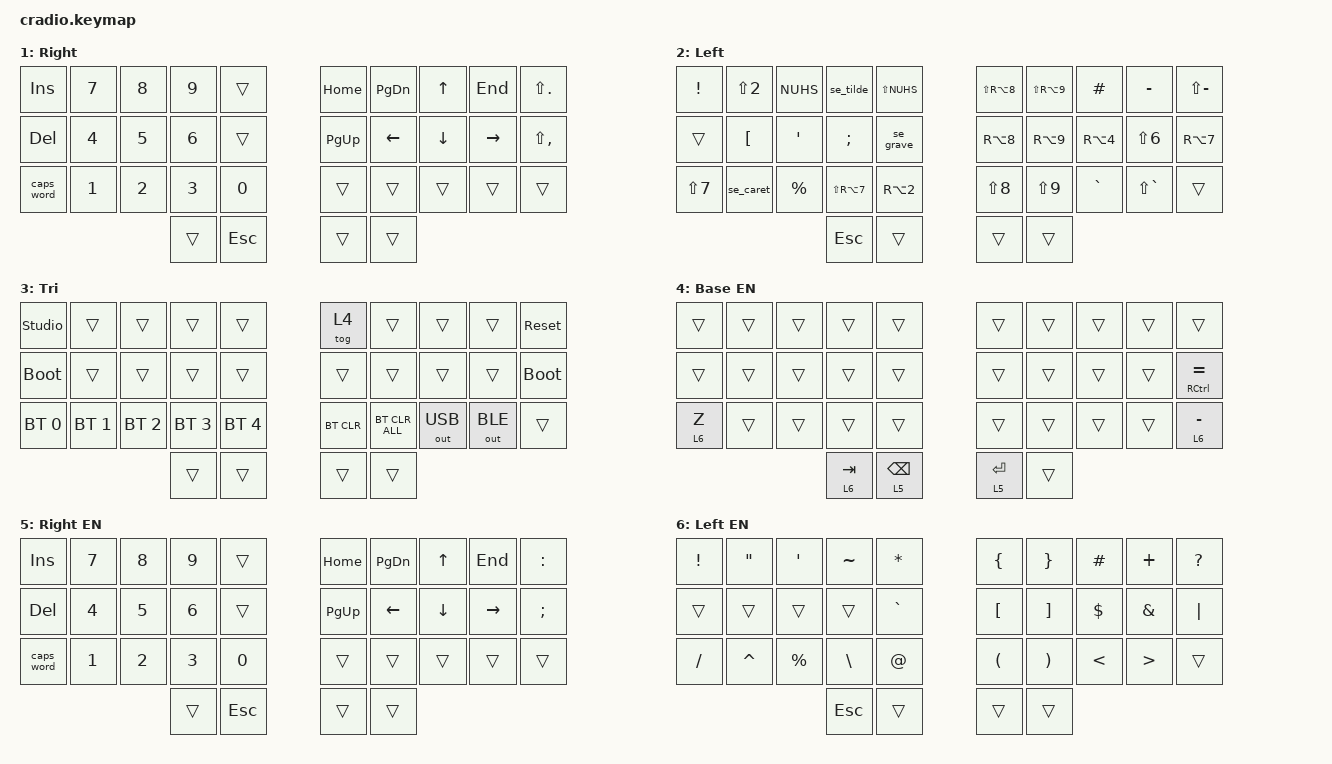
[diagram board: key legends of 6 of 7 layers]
/*
 * Zyra FT (Cradio/Sweep) keymap
 *
 * 34 keys, 7 layers: BASE, RIGHT (numbers/navigation), LEFT (symbols), TRI (system),
 * BASE EN, RIGHT EN, LEFT EN (English-OS secondary layers, macOS-targeted)
 * Home-row mods: Ctrl/Alt/Gui/Shift on the left (A/S/D/F), mirrored on the right (J/K/L/=)
 * ZMK Studio compatible (left = central, USB)
 *
 * No nice!view - pin D1 (P0.06) is used by the Sweep switch matrix.
 *
 * The TRI layer activates when both thumb layers (RIGHT and LEFT) are pressed.
 *
 * studio_unlock = TRI layer + Q (that is, LT(2,TAB) + LT(1,BSPC) + Q)
 *
 * The LEFT (symbols) layer is reachable three ways: hold the TAB thumb key, or
 * hold either bottom-row outermost key (Z on the left half, - on the right half -
 * both still tap their normal character). Whichever entry point is used, holding
 * it and tapping the TAB thumb key (now free) sends Escape. "/" moved to the
 * symbols layer itself (left column, bottom row).
 *
 * Arrow keys live in an IJKL cluster on the RIGHT layer: I/J/K/L = Up/Left/Down/Right,
 * with Home/PgDn/End on Y/U/O and PgUp on H (displaced from I to make room for Up).
 *
 * Swedish letters (Å/Ä/Ö) live on the LEFT layer's home row (only in the Swedish
 * layer set - the English layer set has no single-key way to type them).
 *
 * Language layout: the keyboard defaults to a Swedish OS keyboard layout (layers
 * 0-2). Press LANG (on Tri) to toggle a secondary layer set (layers 4-6) that
 * compensates for an English (US) OS keyboard layout instead, so the same physical
 * keys always produce the same characters regardless of which language the OS is
 * set to. The English secondary layers are targeted primarily at macOS; only the
 * "{", "}", "|" and "\" keys would need adjusting for Windows/Linux.
 */

#include <behaviors.dtsi>
#include <dt-bindings/zmk/keys.h>
#include <dt-bindings/zmk/bt.h>
#include <dt-bindings/zmk/outputs.h>

// Home-row mods - left to right: Ctrl/Alt/Gui/Shift on A/S/D/F
#define HRML(k1,k2,k3,k4) &ht LCTRL k1  &ht LALT k2  &ht LGUI k3  &ht LSHFT k4
// Right hand mirrored: Shift/Gui/Alt/Ctrl on J/K/L/'
#define HRMR(k1,k2,k3,k4) &ht RSHFT k1  &ht RGUI k2  &ht RALT k3  &ht RCTRL k4

/ {
    behaviors {
        bspc_lt: backspace_layer_tap {
            compatible = "zmk,behavior-hold-tap";
            #binding-cells = <2>;
            flavor = "tap-preferred";
            tapping-term-ms = <200>;
            quick-tap-ms = <200>;
            bindings = <&mo>, <&kp>;
        };

        ht: hold_tap {
            compatible = "zmk,behavior-hold-tap";
            #binding-cells = <2>;
            flavor = "tap-preferred";
            tapping-term-ms = <220>;
            quick-tap-ms = <150>;
            require-prior-idle-ms = <100>;
            bindings = <&kp>, <&kp>;
        };
    };

    // Swedish dead-key defeat macros: tap the dead key then Space so the bare
    // character (^, ~, `) is produced immediately instead of waiting to combine
    // with the next key press. These use the Swedish-Mac physical key combos
    // (Shift+]-key, AltGr+]-key, Shift+=-key), not the US CARET/TILDE/GRAVE
    // keycodes, since those map to different physical keys on a Swedish layout.
    macros {
        se_caret: se_caret {
            compatible = "zmk,behavior-macro";
            #binding-cells = <0>;
            bindings = <&kp LS(RBKT) &kp SPACE>;
        };

        se_tilde: se_tilde {
            compatible = "zmk,behavior-macro";
            #binding-cells = <0>;
            bindings = <&kp RA(RBKT) &kp SPACE>;
        };

        se_grave: se_grave {
            compatible = "zmk,behavior-macro";
            #binding-cells = <0>;
            bindings = <&kp LS(EQUAL) &kp SPACE>;
        };
    };

    // Layer 1 (RIGHT) + Layer 2 (LEFT) simultaneously -> Layer 3 (TRI)
    // Layer 5 (RIGHT EN) + Layer 6 (LEFT EN) simultaneously -> Layer 3 (TRI)
    conditional_layers {
        compatible = "zmk,conditional-layers";
        tri_layer {
            if-layers = <1 2>;
            then-layer = <3>;
        };
        tri_layer_en {
            if-layers = <5 6>;
            then-layer = <3>;
        };
    };

    keymap {
        compatible = "zmk,keymap";

        // Swedish (default) base layer.
        default_layer {
            display-name = "Base";
            bindings = <
        //╭──────────┬──────────┬──────────┬──────────┬──────────╮   ╭──────────┬──────────┬──────────┬──────────┬──────────╮
        //│  Q       │  W       │  E       │  R       │  T       │   │  Y       │  U       │  I       │  O       │  P       │
            &kp Q      &kp W      &kp E      &kp R      &kp T          &kp Y      &kp U      &kp I      &kp O      &kp P
        //├──────────┼──────────┼──────────┼──────────┼──────────┤   ├──────────┼──────────┼──────────┼──────────┼──────────┤
        //│  A (Sft) │  S (Alt) │  D (Ctl) │  F (Gui) │  G       │   │  H       │  J (Gui) │  K (Ctl) │  L (Alt) │  = (Sft) │
            HRML(A,        S,         D,         F)     &kp G          &kp H      HRMR(J,        K,         L,        LS(N0))
        //├──────────┼──────────┼──────────┼──────────┼──────────┤   ├──────────┼──────────┼──────────┼──────────┼──────────┤
        //│ Z (Sym)  │  X       │  C       │  V       │  B       │   │  N       │  M       │ , <      │ . >      │ - (Sym)  │
            &lt 2 Z    &kp X      &kp C      &kp V      &kp B          &kp N      &kp M      &kp COMMA  &kp DOT    &lt 2 FSLH
        //╰──────────┴──────────┴──────────┼──────────┼──────────┤   ├──────────┼──────────┼──────────┴──────────┴──────────╯
                                            &lt 2 TAB   &bspc_lt 1 BSPC &lt 1 ENTER &kp SPACE
        //                                 ╰──────────┴──────────╯   ╰──────────┴──────────╯
            >;
        };

        // Swedish numbers/navigation layer.
        right_layer {
            display-name = "Right";
            bindings = <
        //╭──────────┬──────────┬──────────┬──────────┬──────────╮   ╭──────────┬──────────┬──────────┬──────────┬──────────╮
        //│ INSERT   │  7       │  8       │  9       │          │   │ HOME     │ PAGE DN  │ UP       │ END      │  :       │
            &kp INS    &kp N7     &kp N8     &kp N9     &trans         &kp HOME   &kp PG_DN  &kp UP     &kp END    &kp LS(DOT)
        //├──────────┼──────────┼──────────┼──────────┼──────────┤   ├──────────┼──────────┼──────────┼──────────┼──────────┤
        //│ DELETE   │  4       │  5       │  6       │          │   │ PAGE UP  │ LEFT     │ DOWN     │ RIGHT    │  ;       │
            &kp DEL    &kp N4     &kp N5     &kp N6     &trans         &kp PG_UP  &kp LEFT   &kp DOWN   &kp RIGHT  &kp LS(COMMA)
        //├──────────┼──────────┼──────────┼──────────┼──────────┤   ├──────────┼──────────┼──────────┼──────────┼──────────┤
        //│ CAPS WORD│  1       │  2       │  3       │  0       │   │          │          │          │          │          │
           &caps_word  &kp N1     &kp N2     &kp N3     &kp N0         &trans     &trans     &trans     &trans     &trans
        //╰──────────┴──────────┴──────────┼──────────┼──────────┤   ├──────────┼──────────┼──────────┴──────────┴──────────╯
                                             &trans     &kp ESC        &trans     &trans
        //                                 ╰──────────┴──────────╯   ╰──────────┴──────────╯
            >;
        };

        // Swedish symbols layer. Reachable via TAB, Z or "-" (see default_layer). ESC
        // sits on the TAB thumb-key position, since it's free whenever this layer was
        // entered via Z or "-" instead. Layout follows the ZSA Voyager symbols layer:
        // quotes/tilde/asterisk on the top row, Swedish letters (Å/Ä/Ö) and grave on the
        // home row, "/" (moved off the base layer) plus ^/%/\/@ on the bottom row.
        left_layer {
            display-name = "Left";
            bindings = <
        //╭──────────┬──────────┬──────────┬──────────┬──────────╮   ╭──────────┬──────────┬──────────┬──────────┬──────────╮
        //│  !       │  "       │  '       │  ~       │  *       │   │  {       │  }       │  #       │  +       │  ?       │
            &kp EXCL   &kp LS(N2) &kp NUHS   &se_tilde  &kp LS(NUHS)   &kp LS(RA(N8)) &kp LS(RA(N9)) &kp HASH &kp MINUS &kp LS(MINUS)
        //├──────────┼──────────┼──────────┼──────────┼──────────┤   ├──────────┼──────────┼──────────┼──────────┼──────────┤
        //│          │  Å       │  Ä       │  Ö       │  `       │   │  [       │  ]       │  $       │  &       │  │       │
            &trans     &kp LBKT   &kp SQT    &kp SEMI   &se_grave      &kp RA(N8) &kp RA(N9) &kp RA(N4) &kp LS(N6) &kp RA(N7)
        //├──────────┼──────────┼──────────┼──────────┼──────────┤   ├──────────┼──────────┼──────────┼──────────┼──────────┤
        //│  /       │  ^       │  %       │  \       │  @       │   │  (       │  )       │  <       │  >       │          │
            &kp LS(N7) &se_caret  &kp PRCNT  &kp LS(RA(N7)) &kp RA(N2) &kp LS(N8) &kp LS(N9) &kp GRAVE  &kp LS(GRAVE) &trans
        //╰──────────┴──────────┴──────────┼──────────┼──────────┤   ├──────────┼──────────┼──────────┴──────────┴──────────╯
                                            &kp ESC     &trans         &trans     &trans
        //                                 ╰──────────┴──────────╯   ╰──────────┴──────────╯
            >;
        };

        tri_layer {
            display-name = "Tri";
            bindings = <
        //╭──────────┬──────────┬──────────┬──────────┬──────────╮   ╭──────────┬──────────┬──────────┬──────────┬──────────╮
        //│ STUDIO   │          │          │          │          │   │ LANG     │          │          │          │ RESET    │
          &studio_unlock &trans     &trans     &trans     &trans         &tog 4     &trans     &trans     &trans     &sys_reset
        //├──────────┼──────────┼──────────┼──────────┼──────────┤   ├──────────┼──────────┼──────────┼──────────┼──────────┤
        //│ BOOT     │          │          │          │          │   │          │          │          │          │ BOOT     │
          &bootloader  &trans       &trans     &trans     &trans         &trans     &trans     &trans     &trans   &bootloader
        //├──────────┼──────────┼──────────┼──────────┼──────────┤   ├──────────┼──────────┼──────────┼──────────┼──────────┤
        //│ BT 0     │ BT 1     │ BT 2     │ BT 3     │ BT 4     │   │ BT CLR   │ BT CLRALL│ USB      │ BLE      │          │
        &bt BT_SEL 0 &bt BT_SEL 1 &bt BT_SEL 2 &bt BT_SEL 3 &bt BT_SEL 4   &bt BT_CLR &bt BT_CLR_ALL &out OUT_USB &out OUT_BLE &trans
        //╰──────────┴──────────┴──────────┼──────────┼──────────┤   ├──────────┼──────────┼──────────┴──────────┴──────────╯
                                             &trans     &trans         &trans     &trans
        //                                 ╰──────────┴──────────╯   ╰──────────┴──────────╯
            >;
        };

        // English (secondary) base layer. Overlays default_layer (toggled via LANG on Tri).
        // Letters are untouched (identical on US and Swedish keyboards); only the equals
        // key and the thumb layer-taps (pointing at right_layer_en/left_layer_en) change.
        default_layer_en {
            display-name = "Base EN";
            bindings = <
        //╭──────────┬──────────┬──────────┬──────────┬──────────╮   ╭──────────┬──────────┬──────────┬──────────┬──────────╮
        //│          │          │          │          │          │   │          │          │          │          │          │
            &trans     &trans     &trans     &trans     &trans         &trans     &trans     &trans     &trans     &trans
        //├──────────┼──────────┼──────────┼──────────┼──────────┤   ├──────────┼──────────┼──────────┼──────────┼──────────┤
        //│          │          │          │          │          │   │          │          │          │          │  = (Sft) │
            &trans     &trans     &trans     &trans     &trans         &trans     &trans     &trans     &trans     &ht RCTRL EQUAL
        //├──────────┼──────────┼──────────┼──────────┼──────────┤   ├──────────┼──────────┼──────────┼──────────┼──────────┤
        //│ Z (Sym)  │          │          │          │          │   │          │          │          │          │ - (Sym)  │
            &lt 6 Z     &trans     &trans     &trans     &trans         &trans     &trans     &trans     &trans     &lt 6 MINUS
        //╰──────────┴──────────┴──────────┼──────────┼──────────┤   ├──────────┼──────────┼──────────┴──────────┴──────────╯
                                            &lt 6 TAB   &bspc_lt 5 BSPC &lt 5 ENTER &trans
        //                                 ╰──────────┴──────────╯   ╰──────────┴──────────╯
            >;
        };

        // English (secondary) numbers/navigation layer. Fully self-contained: it is a
        // momentary layer, so it cannot rely on falling through to right_layer (which is
        // never active at the same time).
        right_layer_en {
            display-name = "Right EN";
            bindings = <
        //╭──────────┬──────────┬──────────┬──────────┬──────────╮   ╭──────────┬──────────┬──────────┬──────────┬──────────╮
        //│ INSERT   │  7       │  8       │  9       │          │   │ HOME     │ PAGE DN  │ UP       │ END      │  :       │
            &kp INS    &kp N7     &kp N8     &kp N9     &trans         &kp HOME   &kp PG_DN  &kp UP     &kp END    &kp COLON
        //├──────────┼──────────┼──────────┼──────────┼──────────┤   ├──────────┼──────────┼──────────┼──────────┼──────────┤
        //│ DELETE   │  4       │  5       │  6       │          │   │ PAGE UP  │ LEFT     │ DOWN     │ RIGHT    │  ;       │
            &kp DEL    &kp N4     &kp N5     &kp N6     &trans         &kp PG_UP  &kp LEFT   &kp DOWN   &kp RIGHT  &kp SEMI
        //├──────────┼──────────┼──────────┼──────────┼──────────┤   ├──────────┼──────────┼──────────┼──────────┼──────────┤
        //│ CAPS WORD│  1       │  2       │  3       │  0       │   │          │          │          │          │          │
           &caps_word  &kp N1     &kp N2     &kp N3     &kp N0         &trans     &trans     &trans     &trans     &trans
        //╰──────────┴──────────┴──────────┼──────────┼──────────┤   ├──────────┼──────────┼──────────┴──────────┴──────────╯
                                             &trans     &kp ESC        &trans     &trans
        //                                 ╰──────────┴──────────╯   ╰──────────┴──────────╯
            >;
        };

        // English (secondary) symbols layer. Reachable via TAB, Z or "-" (see
        // default_layer_en). ESC sits on the TAB thumb-key position, same as left_layer.
        // Same layout as left_layer, using raw US keycodes; no single-key Å/Ä/Ö exist on
        // an English OS, so those slots stay transparent.
        left_layer_en {
            display-name = "Left EN";
            bindings = <
        //╭──────────┬──────────┬──────────┬──────────┬──────────╮   ╭──────────┬──────────┬──────────┬──────────┬──────────╮
        //│  !       │  "       │  '       │  ~       │  *       │   │  {       │  }       │  #       │  +       │  ?       │
            &kp EXCL   &kp DQT    &kp SQT    &kp TILDE  &kp ASTRK      &kp LBRC   &kp RBRC   &kp HASH   &kp PLUS   &kp QMARK
        //├──────────┼──────────┼──────────┼──────────┼──────────┤   ├──────────┼──────────┼──────────┼──────────┼──────────┤
        //│          │          │          │          │  `       │   │  [       │  ]       │  $       │  &       │  │       │
            &trans     &trans     &trans     &trans     &kp GRAVE      &kp LBKT   &kp RBKT   &kp DLLR   &kp AMPS   &kp PIPE
        //├──────────┼──────────┼──────────┼──────────┼──────────┤   ├──────────┼──────────┼──────────┼──────────┼──────────┤
        //│  /       │  ^       │  %       │  \       │  @       │   │  (       │  )       │  <       │  >       │          │
            &kp FSLH   &kp CARET  &kp PRCNT  &kp BSLH   &kp AT         &kp LPAR   &kp RPAR   &kp LT     &kp GT     &trans
        //╰──────────┴──────────┴──────────┼──────────┼──────────┤   ├──────────┼──────────┼──────────┴──────────┴──────────╯
                                            &kp ESC     &trans         &trans     &trans
        //                                 ╰──────────┴──────────╯   ╰──────────┴──────────╯
            >;
        };
    };
};
